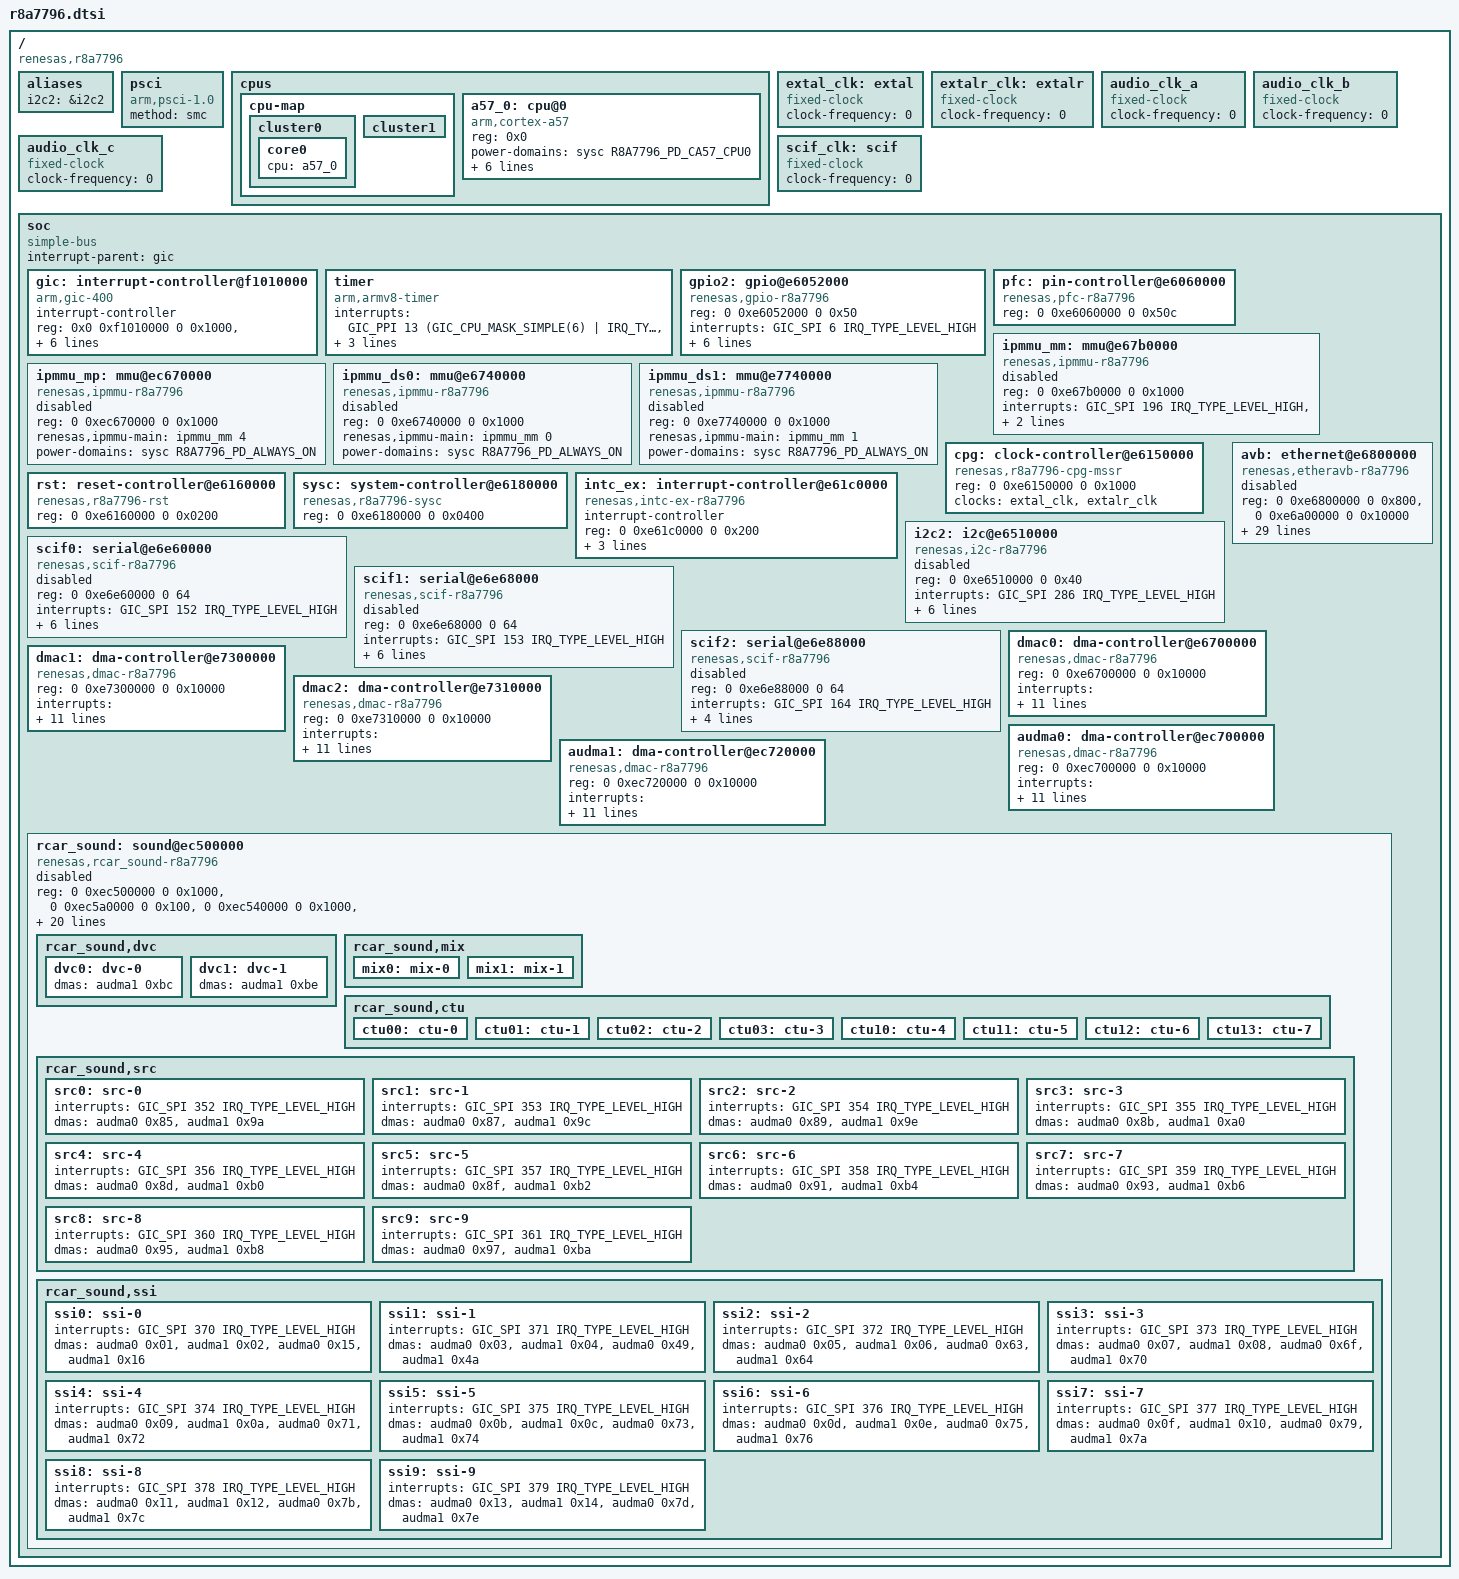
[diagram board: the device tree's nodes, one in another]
/*
 * Device Tree Source for the r8a7796 SoC
 *
 * Copyright (C) 2016-2018 Renesas Electronics Corp.
 *
 * This file is licensed under the terms of the GNU General Public License
 * version 2.  This program is licensed "as is" without any warranty of any
 * kind, whether express or implied.
 */

#include <dt-bindings/clock/r8a7796-cpg-mssr.h>
#include <dt-bindings/interrupt-controller/arm-gic.h>
#include <dt-bindings/power/r8a7796-sysc.h>

#define CPG_AUDIO_CLK_I		R8A7796_CLK_S0D4

/ {
	compatible = "renesas,r8a7796";
	#address-cells = <2>;
	#size-cells = <2>;

	aliases {
		i2c2 = &i2c2;
	};

	psci {
		compatible = "arm,psci-1.0", "arm,psci-0.2";
		method = "smc";
	};

	cpus {
		#address-cells = <1>;
		#size-cells = <0>;

		cpu-map {
			cluster0 {
				core0 {
					cpu = <&a57_0>;
				};
			};

			cluster1 {
			};
		};

		a57_0: cpu@0 {
			compatible = "arm,cortex-a57", "arm,armv8";
			reg = <0x0>;
			device_type = "cpu";
			power-domains = <&sysc R8A7796_PD_CA57_CPU0>;
			enable-method = "psci";
			#cooling-cells = <2>;
			dynamic-power-coefficient = <854>;
			cooling-min-level = <0>;
			cooling-max-level = <2>;
			clocks =<&cpg CPG_CORE R8A7796_CLK_Z>;
			capacity-dmips-mhz = <1024>;
		};
	};

	extal_clk: extal {
		compatible = "fixed-clock";
		#clock-cells = <0>;
		/* This value must be overridden by the board */
		clock-frequency = <0>;
	};

	extalr_clk: extalr {
		compatible = "fixed-clock";
		#clock-cells = <0>;
		/* This value must be overridden by the board */
		clock-frequency = <0>;
	};

	/*
	 * The external audio clocks are configured as 0 Hz fixed frequency
	 * clocks by default.
	 * Boards that provide audio clocks should override them.
	 */
	audio_clk_a: audio_clk_a {
		compatible = "fixed-clock";
		#clock-cells = <0>;
		clock-frequency = <0>;
	};

	audio_clk_b: audio_clk_b {
		compatible = "fixed-clock";
		#clock-cells = <0>;
		clock-frequency = <0>;
	};

	audio_clk_c: audio_clk_c {
		compatible = "fixed-clock";
		#clock-cells = <0>;
		clock-frequency = <0>;
	};


	/* External SCIF clock - to be overridden by boards that provide it */
	scif_clk: scif {
		compatible = "fixed-clock";
		#clock-cells = <0>;
		clock-frequency = <0>;
	};

	soc {
		compatible = "simple-bus";
		interrupt-parent = <&gic>;
		#address-cells = <2>;
		#size-cells = <2>;
		ranges;

		gic: interrupt-controller@f1010000 {
			compatible = "arm,gic-400";
			#interrupt-cells = <3>;
			#address-cells = <0>;
			interrupt-controller;
			reg = <0x0 0xf1010000 0 0x1000>,
			      <0x0 0xf1020000 0 0x20000>,
			      <0x0 0xf1040000 0 0x20000>,
			      <0x0 0xf1060000 0 0x20000>;
			interrupts = <GIC_PPI 9
					(GIC_CPU_MASK_SIMPLE(6) | IRQ_TYPE_LEVEL_HIGH)>;
			power-domains = <&sysc R8A7796_PD_ALWAYS_ON>;
		};

		timer {
			compatible = "arm,armv8-timer";
			interrupts = <GIC_PPI 13
					(GIC_CPU_MASK_SIMPLE(6) | IRQ_TYPE_LEVEL_LOW)>,
				     <GIC_PPI 14
					(GIC_CPU_MASK_SIMPLE(6) | IRQ_TYPE_LEVEL_LOW)>,
				     <GIC_PPI 11
					(GIC_CPU_MASK_SIMPLE(6) | IRQ_TYPE_LEVEL_LOW)>,
				     <GIC_PPI 10
					(GIC_CPU_MASK_SIMPLE(6) | IRQ_TYPE_LEVEL_LOW)>;
		};

		gpio2: gpio@e6052000 {
			compatible = "renesas,gpio-r8a7796",
				     "renesas,rcar-gen3-gpio";
			reg = <0 0xe6052000 0 0x50>;
			interrupts = <GIC_SPI 6 IRQ_TYPE_LEVEL_HIGH>;
			#gpio-cells = <2>;
			gpio-controller;
			gpio-ranges = <&pfc 0 64 15>;
			#interrupt-cells = <2>;
			interrupt-controller;
			clocks = <&cpg CPG_MOD 910>;
			power-domains = <&sysc R8A7796_PD_ALWAYS_ON>;
			resets = <&cpg 910>;
		};

		pfc: pin-controller@e6060000 {
			compatible = "renesas,pfc-r8a7796";
			reg = <0 0xe6060000 0 0x50c>;
		};


		ipmmu_mm: mmu@e67b0000 {
			compatible = "renesas,ipmmu-r8a7796";
			reg = <0 0xe67b0000 0 0x1000>;
			interrupts = <GIC_SPI 196 IRQ_TYPE_LEVEL_HIGH>,
				     <GIC_SPI 197 IRQ_TYPE_LEVEL_HIGH>;
			power-domains = <&sysc R8A7796_PD_ALWAYS_ON>;
			#iommu-cells = <1>;
			status = "disabled";
		};

		ipmmu_mp: mmu@ec670000 {
			compatible = "renesas,ipmmu-r8a7796";
			reg = <0 0xec670000 0 0x1000>;
			renesas,ipmmu-main = <&ipmmu_mm 4>;
			power-domains = <&sysc R8A7796_PD_ALWAYS_ON>;
			#iommu-cells = <1>;
			status = "disabled";
		};

		ipmmu_ds0: mmu@e6740000 {
			compatible = "renesas,ipmmu-r8a7796";
			reg = <0 0xe6740000 0 0x1000>;
			renesas,ipmmu-main = <&ipmmu_mm 0>;
			power-domains = <&sysc R8A7796_PD_ALWAYS_ON>;
			#iommu-cells = <1>;
			status = "disabled";
		};

		ipmmu_ds1: mmu@e7740000 {
			compatible = "renesas,ipmmu-r8a7796";
			reg = <0 0xe7740000 0 0x1000>;
			renesas,ipmmu-main = <&ipmmu_mm 1>;
			power-domains = <&sysc R8A7796_PD_ALWAYS_ON>;
			#iommu-cells = <1>;
			status = "disabled";
		};

		cpg: clock-controller@e6150000 {
			compatible = "renesas,r8a7796-cpg-mssr";
			reg = <0 0xe6150000 0 0x1000>;
			clocks = <&extal_clk>, <&extalr_clk>;
			clock-names = "extal", "extalr";
			#clock-cells = <2>;
			#power-domain-cells = <0>;
			#reset-cells = <1>;
		};

		rst: reset-controller@e6160000 {
			compatible = "renesas,r8a7796-rst";
			reg = <0 0xe6160000 0 0x0200>;
		};

		sysc: system-controller@e6180000 {
			compatible = "renesas,r8a7796-sysc";
			reg = <0 0xe6180000 0 0x0400>;
			#power-domain-cells = <1>;
		};

		intc_ex: interrupt-controller@e61c0000 {
			compatible = "renesas,intc-ex-r8a7796", "renesas,irqc";
			#interrupt-cells = <2>;
			interrupt-controller;
			reg = <0 0xe61c0000 0 0x200>;
			interrupts = <GIC_SPI 0 IRQ_TYPE_LEVEL_HIGH
				      GIC_SPI 1 IRQ_TYPE_LEVEL_HIGH
				      GIC_SPI 2 IRQ_TYPE_LEVEL_HIGH
				      GIC_SPI 3 IRQ_TYPE_LEVEL_HIGH
				      GIC_SPI 18 IRQ_TYPE_LEVEL_HIGH
				      GIC_SPI 161 IRQ_TYPE_LEVEL_HIGH>;
			power-domains = <&sysc R8A7796_PD_ALWAYS_ON>;
		};

		i2c2: i2c@e6510000 {
			#address-cells = <1>;
			#size-cells = <0>;
			compatible = "renesas,i2c-r8a7796",
				     "renesas,rcar-gen3-i2c";
			reg = <0 0xe6510000 0 0x40>;
			interrupts = <GIC_SPI 286 IRQ_TYPE_LEVEL_HIGH>;
			clocks = <&cpg CPG_MOD 929>;
			power-domains = <&sysc R8A7796_PD_ALWAYS_ON>;
			resets = <&cpg 929>;
			dmas = <&dmac1 0x95>, <&dmac1 0x94>,
			       <&dmac2 0x95>, <&dmac2 0x94>;
			dma-names = "tx", "rx", "tx", "rx";
			i2c-scl-internal-delay-ns = <6>;
			status = "disabled";
		};

		avb: ethernet@e6800000 {
			compatible = "renesas,etheravb-r8a7796",
				     "renesas,etheravb-rcar-gen3";
			reg = <0 0xe6800000 0 0x800>, <0 0xe6a00000 0 0x10000>;
			interrupts = <GIC_SPI 39 IRQ_TYPE_LEVEL_HIGH>,
				     <GIC_SPI 40 IRQ_TYPE_LEVEL_HIGH>,
				     <GIC_SPI 41 IRQ_TYPE_LEVEL_HIGH>,
				     <GIC_SPI 42 IRQ_TYPE_LEVEL_HIGH>,
				     <GIC_SPI 43 IRQ_TYPE_LEVEL_HIGH>,
				     <GIC_SPI 44 IRQ_TYPE_LEVEL_HIGH>,
				     <GIC_SPI 45 IRQ_TYPE_LEVEL_HIGH>,
				     <GIC_SPI 46 IRQ_TYPE_LEVEL_HIGH>,
				     <GIC_SPI 47 IRQ_TYPE_LEVEL_HIGH>,
				     <GIC_SPI 48 IRQ_TYPE_LEVEL_HIGH>,
				     <GIC_SPI 49 IRQ_TYPE_LEVEL_HIGH>,
				     <GIC_SPI 50 IRQ_TYPE_LEVEL_HIGH>,
				     <GIC_SPI 51 IRQ_TYPE_LEVEL_HIGH>,
				     <GIC_SPI 52 IRQ_TYPE_LEVEL_HIGH>,
				     <GIC_SPI 53 IRQ_TYPE_LEVEL_HIGH>,
				     <GIC_SPI 54 IRQ_TYPE_LEVEL_HIGH>,
				     <GIC_SPI 55 IRQ_TYPE_LEVEL_HIGH>,
				     <GIC_SPI 56 IRQ_TYPE_LEVEL_HIGH>,
				     <GIC_SPI 57 IRQ_TYPE_LEVEL_HIGH>,
				     <GIC_SPI 58 IRQ_TYPE_LEVEL_HIGH>,
				     <GIC_SPI 59 IRQ_TYPE_LEVEL_HIGH>,
				     <GIC_SPI 60 IRQ_TYPE_LEVEL_HIGH>,
				     <GIC_SPI 61 IRQ_TYPE_LEVEL_HIGH>,
				     <GIC_SPI 62 IRQ_TYPE_LEVEL_HIGH>,
				     <GIC_SPI 63 IRQ_TYPE_LEVEL_HIGH>;
			interrupt-names = "ch0", "ch1", "ch2", "ch3",
					  "ch4", "ch5", "ch6", "ch7",
					  "ch8", "ch9", "ch10", "ch11",
					  "ch12", "ch13", "ch14", "ch15",
					  "ch16", "ch17", "ch18", "ch19",
					  "ch20", "ch21", "ch22", "ch23",
					  "ch24";
			clocks = <&cpg CPG_MOD 812>;
			power-domains = <&sysc R8A7796_PD_ALWAYS_ON>;
			resets = <&cpg 812>;
			phy-mode = "rgmii-txid";
			#address-cells = <1>;
			#size-cells = <0>;
			status = "disabled";
		};

		scif0: serial@e6e60000 {
			compatible = "renesas,scif-r8a7796",
				     "renesas,rcar-gen3-scif", "renesas,scif";
			reg = <0 0xe6e60000 0 64>;
			interrupts = <GIC_SPI 152 IRQ_TYPE_LEVEL_HIGH>;
			clocks = <&cpg CPG_MOD 207>,
				 <&cpg CPG_CORE R8A7796_CLK_S3D1>,
				 <&scif_clk>;
			clock-names = "fck", "brg_int", "scif_clk";
			dmas = <&dmac1 0x51>, <&dmac1 0x50>,
			       <&dmac2 0x51>, <&dmac2 0x50>;
			dma-names = "tx", "rx", "tx", "rx";
			power-domains = <&sysc R8A7796_PD_ALWAYS_ON>;
			resets = <&cpg 207>;
			status = "disabled";
		};

		scif1: serial@e6e68000 {
			compatible = "renesas,scif-r8a7796",
				     "renesas,rcar-gen3-scif", "renesas,scif";
			reg = <0 0xe6e68000 0 64>;
			interrupts = <GIC_SPI 153 IRQ_TYPE_LEVEL_HIGH>;
			clocks = <&cpg CPG_MOD 206>,
				 <&cpg CPG_CORE R8A7796_CLK_S3D1>,
				 <&scif_clk>;
			clock-names = "fck", "brg_int", "scif_clk";
			dmas = <&dmac1 0x53>, <&dmac1 0x52>,
			       <&dmac2 0x53>, <&dmac2 0x52>;
			dma-names = "tx", "rx", "tx", "rx";
			power-domains = <&sysc R8A7796_PD_ALWAYS_ON>;
			resets = <&cpg 206>;
			status = "disabled";
		};


		scif2: serial@e6e88000 {
			compatible = "renesas,scif-r8a7796",
				     "renesas,rcar-gen3-scif", "renesas,scif";
			reg = <0 0xe6e88000 0 64>;
			interrupts = <GIC_SPI 164 IRQ_TYPE_LEVEL_HIGH>;
			clocks = <&cpg CPG_MOD 310>,
				 <&cpg CPG_CORE R8A7796_CLK_S3D1>,
				 <&scif_clk>;
			clock-names = "fck", "brg_int", "scif_clk";
			power-domains = <&sysc R8A7796_PD_ALWAYS_ON>;
			resets = <&cpg 310>;
			status = "disabled";
		};


		dmac0: dma-controller@e6700000 {
			compatible = "renesas,dmac-r8a7796",
				     "renesas,rcar-dmac";
			reg = <0 0xe6700000 0 0x10000>;
			interrupts = <GIC_SPI 200 IRQ_TYPE_LEVEL_HIGH
				      GIC_SPI 201 IRQ_TYPE_LEVEL_HIGH
				      GIC_SPI 202 IRQ_TYPE_LEVEL_HIGH
				      GIC_SPI 203 IRQ_TYPE_LEVEL_HIGH
				      GIC_SPI 204 IRQ_TYPE_LEVEL_HIGH
				      GIC_SPI 205 IRQ_TYPE_LEVEL_HIGH
				      GIC_SPI 206 IRQ_TYPE_LEVEL_HIGH
				      GIC_SPI 207 IRQ_TYPE_LEVEL_HIGH
				      GIC_SPI 208 IRQ_TYPE_LEVEL_HIGH
				      GIC_SPI 209 IRQ_TYPE_LEVEL_HIGH
				      GIC_SPI 210 IRQ_TYPE_LEVEL_HIGH
				      GIC_SPI 211 IRQ_TYPE_LEVEL_HIGH
				      GIC_SPI 212 IRQ_TYPE_LEVEL_HIGH
				      GIC_SPI 213 IRQ_TYPE_LEVEL_HIGH
				      GIC_SPI 214 IRQ_TYPE_LEVEL_HIGH
				      GIC_SPI 215 IRQ_TYPE_LEVEL_HIGH>;
			interrupt-names = "ch0", "ch1", "ch2", "ch3",
					"ch4", "ch5", "ch6", "ch7",
					"ch8", "ch9", "ch10", "ch11",
					"ch12", "ch13", "ch14", "ch15";
			clocks = <&cpg CPG_MOD 219>;
			clock-names = "fck";
			power-domains = <&sysc R8A7796_PD_ALWAYS_ON>;
			resets = <&cpg 219>;
			#dma-cells = <1>;
			dma-channels = <16>;
			iommus = <&ipmmu_ds0 0>, <&ipmmu_ds0 1>,
			       <&ipmmu_ds0 2>, <&ipmmu_ds0 3>,
			       <&ipmmu_ds0 4>, <&ipmmu_ds0 5>,
			       <&ipmmu_ds0 6>, <&ipmmu_ds0 7>,
			       <&ipmmu_ds0 8>, <&ipmmu_ds0 9>,
			       <&ipmmu_ds0 10>, <&ipmmu_ds0 11>,
			       <&ipmmu_ds0 12>, <&ipmmu_ds0 13>,
			       <&ipmmu_ds0 14>, <&ipmmu_ds0 15>;
		};

		dmac1: dma-controller@e7300000 {
			compatible = "renesas,dmac-r8a7796",
				     "renesas,rcar-dmac";
			reg = <0 0xe7300000 0 0x10000>;
			interrupts = <GIC_SPI 216 IRQ_TYPE_LEVEL_HIGH
				      GIC_SPI 217 IRQ_TYPE_LEVEL_HIGH
				      GIC_SPI 218 IRQ_TYPE_LEVEL_HIGH
				      GIC_SPI 219 IRQ_TYPE_LEVEL_HIGH
				      GIC_SPI 308 IRQ_TYPE_LEVEL_HIGH
				      GIC_SPI 309 IRQ_TYPE_LEVEL_HIGH
				      GIC_SPI 310 IRQ_TYPE_LEVEL_HIGH
				      GIC_SPI 311 IRQ_TYPE_LEVEL_HIGH
				      GIC_SPI 312 IRQ_TYPE_LEVEL_HIGH
				      GIC_SPI 313 IRQ_TYPE_LEVEL_HIGH
				      GIC_SPI 314 IRQ_TYPE_LEVEL_HIGH
				      GIC_SPI 315 IRQ_TYPE_LEVEL_HIGH
				      GIC_SPI 316 IRQ_TYPE_LEVEL_HIGH
				      GIC_SPI 317 IRQ_TYPE_LEVEL_HIGH
				      GIC_SPI 318 IRQ_TYPE_LEVEL_HIGH
				      GIC_SPI 319 IRQ_TYPE_LEVEL_HIGH>;
			interrupt-names = "ch0", "ch1", "ch2", "ch3",
					"ch4", "ch5", "ch6", "ch7",
					"ch8", "ch9", "ch10", "ch11",
					"ch12", "ch13", "ch14", "ch15";
			clocks = <&cpg CPG_MOD 218>;
			clock-names = "fck";
			power-domains = <&sysc R8A7796_PD_ALWAYS_ON>;
			resets = <&cpg 218>;
			#dma-cells = <1>;
			dma-channels = <16>;
			iommus = <&ipmmu_ds1 0>, <&ipmmu_ds1 1>,
			       <&ipmmu_ds1 2>, <&ipmmu_ds1 3>,
			       <&ipmmu_ds1 4>, <&ipmmu_ds1 5>,
			       <&ipmmu_ds1 6>, <&ipmmu_ds1 7>,
			       <&ipmmu_ds1 8>, <&ipmmu_ds1 9>,
			       <&ipmmu_ds1 10>, <&ipmmu_ds1 11>,
			       <&ipmmu_ds1 12>, <&ipmmu_ds1 13>,
			       <&ipmmu_ds1 14>, <&ipmmu_ds1 15>;
		};

		dmac2: dma-controller@e7310000 {
			compatible = "renesas,dmac-r8a7796",
				     "renesas,rcar-dmac";
			reg = <0 0xe7310000 0 0x10000>;
			interrupts = <GIC_SPI 417 IRQ_TYPE_LEVEL_HIGH
				      GIC_SPI 418 IRQ_TYPE_LEVEL_HIGH
				      GIC_SPI 419 IRQ_TYPE_LEVEL_HIGH
				      GIC_SPI 420 IRQ_TYPE_LEVEL_HIGH
				      GIC_SPI 421 IRQ_TYPE_LEVEL_HIGH
				      GIC_SPI 422 IRQ_TYPE_LEVEL_HIGH
				      GIC_SPI 423 IRQ_TYPE_LEVEL_HIGH
				      GIC_SPI 424 IRQ_TYPE_LEVEL_HIGH
				      GIC_SPI 425 IRQ_TYPE_LEVEL_HIGH
				      GIC_SPI 426 IRQ_TYPE_LEVEL_HIGH
				      GIC_SPI 427 IRQ_TYPE_LEVEL_HIGH
				      GIC_SPI 428 IRQ_TYPE_LEVEL_HIGH
				      GIC_SPI 429 IRQ_TYPE_LEVEL_HIGH
				      GIC_SPI 430 IRQ_TYPE_LEVEL_HIGH
				      GIC_SPI 431 IRQ_TYPE_LEVEL_HIGH
				      GIC_SPI 397 IRQ_TYPE_LEVEL_HIGH>;
			interrupt-names = "ch0", "ch1", "ch2", "ch3",
					"ch4", "ch5", "ch6", "ch7",
					"ch8", "ch9", "ch10", "ch11",
					"ch12", "ch13", "ch14", "ch15";
			clocks = <&cpg CPG_MOD 217>;
			clock-names = "fck";
			power-domains = <&sysc R8A7796_PD_ALWAYS_ON>;
			resets = <&cpg 217>;
			#dma-cells = <1>;
			dma-channels = <16>;
			iommus = <&ipmmu_ds1 16>, <&ipmmu_ds1 17>,
			       <&ipmmu_ds1 18>, <&ipmmu_ds1 19>,
			       <&ipmmu_ds1 20>, <&ipmmu_ds1 21>,
			       <&ipmmu_ds1 22>, <&ipmmu_ds1 23>,
			       <&ipmmu_ds1 24>, <&ipmmu_ds1 25>,
			       <&ipmmu_ds1 26>, <&ipmmu_ds1 27>,
			       <&ipmmu_ds1 28>, <&ipmmu_ds1 29>,
			       <&ipmmu_ds1 30>, <&ipmmu_ds1 31>;
		};

		audma0: dma-controller@ec700000 {
			compatible = "renesas,dmac-r8a7796",
				     "renesas,rcar-dmac";
			reg = <0 0xec700000 0 0x10000>;
			interrupts = <GIC_SPI 350 IRQ_TYPE_LEVEL_HIGH
				      GIC_SPI 320 IRQ_TYPE_LEVEL_HIGH
				      GIC_SPI 321 IRQ_TYPE_LEVEL_HIGH
				      GIC_SPI 322 IRQ_TYPE_LEVEL_HIGH
				      GIC_SPI 323 IRQ_TYPE_LEVEL_HIGH
				      GIC_SPI 324 IRQ_TYPE_LEVEL_HIGH
				      GIC_SPI 325 IRQ_TYPE_LEVEL_HIGH
				      GIC_SPI 326 IRQ_TYPE_LEVEL_HIGH
				      GIC_SPI 327 IRQ_TYPE_LEVEL_HIGH
				      GIC_SPI 328 IRQ_TYPE_LEVEL_HIGH
				      GIC_SPI 329 IRQ_TYPE_LEVEL_HIGH
				      GIC_SPI 330 IRQ_TYPE_LEVEL_HIGH
				      GIC_SPI 331 IRQ_TYPE_LEVEL_HIGH
				      GIC_SPI 332 IRQ_TYPE_LEVEL_HIGH
				      GIC_SPI 333 IRQ_TYPE_LEVEL_HIGH
				      GIC_SPI 334 IRQ_TYPE_LEVEL_HIGH
				      GIC_SPI 335 IRQ_TYPE_LEVEL_HIGH>;
			interrupt-names = "error",
					"ch0", "ch1", "ch2", "ch3",
					"ch4", "ch5", "ch6", "ch7",
					"ch8", "ch9", "ch10", "ch11",
					"ch12", "ch13", "ch14", "ch15";
			clocks = <&cpg CPG_MOD 502>;
			clock-names = "fck";
			power-domains = <&sysc R8A7796_PD_ALWAYS_ON>;
			resets = <&cpg 502>;
			#dma-cells = <1>;
			dma-channels = <16>;
			iommus = <&ipmmu_mp 0>, <&ipmmu_mp 1>,
			       <&ipmmu_mp 2>, <&ipmmu_mp 3>,
			       <&ipmmu_mp 4>, <&ipmmu_mp 5>,
			       <&ipmmu_mp 6>, <&ipmmu_mp 7>,
			       <&ipmmu_mp 8>, <&ipmmu_mp 9>,
			       <&ipmmu_mp 10>, <&ipmmu_mp 11>,
			       <&ipmmu_mp 12>, <&ipmmu_mp 13>,
			       <&ipmmu_mp 14>, <&ipmmu_mp 15>;
		};

		audma1: dma-controller@ec720000 {
			compatible = "renesas,dmac-r8a7796",
				     "renesas,rcar-dmac";
			reg = <0 0xec720000 0 0x10000>;
			interrupts = <GIC_SPI 351 IRQ_TYPE_LEVEL_HIGH
				      GIC_SPI 336 IRQ_TYPE_LEVEL_HIGH
				      GIC_SPI 337 IRQ_TYPE_LEVEL_HIGH
				      GIC_SPI 338 IRQ_TYPE_LEVEL_HIGH
				      GIC_SPI 339 IRQ_TYPE_LEVEL_HIGH
				      GIC_SPI 340 IRQ_TYPE_LEVEL_HIGH
				      GIC_SPI 341 IRQ_TYPE_LEVEL_HIGH
				      GIC_SPI 342 IRQ_TYPE_LEVEL_HIGH
				      GIC_SPI 343 IRQ_TYPE_LEVEL_HIGH
				      GIC_SPI 344 IRQ_TYPE_LEVEL_HIGH
				      GIC_SPI 345 IRQ_TYPE_LEVEL_HIGH
				      GIC_SPI 346 IRQ_TYPE_LEVEL_HIGH
				      GIC_SPI 347 IRQ_TYPE_LEVEL_HIGH
				      GIC_SPI 348 IRQ_TYPE_LEVEL_HIGH
				      GIC_SPI 349 IRQ_TYPE_LEVEL_HIGH
				      GIC_SPI 382 IRQ_TYPE_LEVEL_HIGH
				      GIC_SPI 383 IRQ_TYPE_LEVEL_HIGH>;
			interrupt-names = "error",
					"ch0", "ch1", "ch2", "ch3",
					"ch4", "ch5", "ch6", "ch7",
					"ch8", "ch9", "ch10", "ch11",
					"ch12", "ch13", "ch14", "ch15";
			clocks = <&cpg CPG_MOD 501>;
			clock-names = "fck";
			power-domains = <&sysc R8A7796_PD_ALWAYS_ON>;
			resets = <&cpg 501>;
			#dma-cells = <1>;
			dma-channels = <16>;
			iommus = <&ipmmu_mp 16>, <&ipmmu_mp 17>,
			       <&ipmmu_mp 18>, <&ipmmu_mp 19>,
			       <&ipmmu_mp 20>, <&ipmmu_mp 21>,
			       <&ipmmu_mp 22>, <&ipmmu_mp 23>,
			       <&ipmmu_mp 24>, <&ipmmu_mp 25>,
			       <&ipmmu_mp 26>, <&ipmmu_mp 27>,
			       <&ipmmu_mp 28>, <&ipmmu_mp 29>,
			       <&ipmmu_mp 30>, <&ipmmu_mp 31>;
		};

		rcar_sound: sound@ec500000 {
			/*
			 * #sound-dai-cells is required
			 *
			 * Single DAI : #sound-dai-cells = <0>;	<&rcar_sound>;
			 * Multi  DAI : #sound-dai-cells = <1>;	<&rcar_sound N>;
			 */
			/*
			 * #clock-cells is required for audio_clkout0/1/2/3
			 *
			 * clkout	: #clock-cells = <0>;	<&rcar_sound>;
			 * clkout0/1/2/3: #clock-cells = <1>;	<&rcar_sound N>;
			 */
			compatible =  "renesas,rcar_sound-r8a7796", "renesas,rcar_sound-gen3";
			reg =	<0 0xec500000 0 0x1000>, /* SCU */
				<0 0xec5a0000 0 0x100>,  /* ADG */
				<0 0xec540000 0 0x1000>, /* SSIU */
				<0 0xec541000 0 0x280>,  /* SSI */
				<0 0xec740000 0 0x200>;  /* Audio DMAC peri peri*/
			reg-names = "scu", "adg", "ssiu", "ssi", "audmapp";

			clocks = <&cpg CPG_MOD 1005>,
				 <&cpg CPG_MOD 1006>, <&cpg CPG_MOD 1007>,
				 <&cpg CPG_MOD 1008>, <&cpg CPG_MOD 1009>,
				 <&cpg CPG_MOD 1010>, <&cpg CPG_MOD 1011>,
				 <&cpg CPG_MOD 1012>, <&cpg CPG_MOD 1013>,
				 <&cpg CPG_MOD 1014>, <&cpg CPG_MOD 1015>,
				 <&cpg CPG_MOD 1022>, <&cpg CPG_MOD 1023>,
				 <&cpg CPG_MOD 1024>, <&cpg CPG_MOD 1025>,
				 <&cpg CPG_MOD 1026>, <&cpg CPG_MOD 1027>,
				 <&cpg CPG_MOD 1028>, <&cpg CPG_MOD 1029>,
				 <&cpg CPG_MOD 1030>, <&cpg CPG_MOD 1031>,
				 <&cpg CPG_MOD 1020>, <&cpg CPG_MOD 1021>,
				 <&cpg CPG_MOD 1020>, <&cpg CPG_MOD 1021>,
				 <&cpg CPG_MOD 1019>, <&cpg CPG_MOD 1018>,
				 <&audio_clk_a>, <&audio_clk_b>,
				 <&audio_clk_c>,
				 <&cpg CPG_CORE R8A7796_CLK_S0D4>;
			clock-names = "ssi-all",
				      "ssi.9", "ssi.8", "ssi.7", "ssi.6",
				      "ssi.5", "ssi.4", "ssi.3", "ssi.2",
				      "ssi.1", "ssi.0",
				      "src.9", "src.8", "src.7", "src.6",
				      "src.5", "src.4", "src.3", "src.2",
				      "src.1", "src.0",
				      "mix.1", "mix.0",
				      "ctu.1", "ctu.0",
				      "dvc.0", "dvc.1",
				      "clk_a", "clk_b", "clk_c", "clk_i";
			power-domains = <&sysc R8A7796_PD_ALWAYS_ON>;
			resets = <&cpg 1005>,
				 <&cpg 1006>, <&cpg 1007>,
				 <&cpg 1008>, <&cpg 1009>,
				 <&cpg 1010>, <&cpg 1011>,
				 <&cpg 1012>, <&cpg 1013>,
				 <&cpg 1014>, <&cpg 1015>;
			reset-names = "ssi-all",
				      "ssi.9", "ssi.8", "ssi.7", "ssi.6",
				      "ssi.5", "ssi.4", "ssi.3", "ssi.2",
				      "ssi.1", "ssi.0";
			status = "disabled";

			rcar_sound,dvc {
				dvc0: dvc-0 {
					dmas = <&audma1 0xbc>;
					dma-names = "tx";
				};
				dvc1: dvc-1 {
					dmas = <&audma1 0xbe>;
					dma-names = "tx";
				};
			};

			rcar_sound,mix {
				mix0: mix-0 { };
				mix1: mix-1 { };
			};

			rcar_sound,ctu {
				ctu00: ctu-0 { };
				ctu01: ctu-1 { };
				ctu02: ctu-2 { };
				ctu03: ctu-3 { };
				ctu10: ctu-4 { };
				ctu11: ctu-5 { };
				ctu12: ctu-6 { };
				ctu13: ctu-7 { };
			};

			rcar_sound,src {
				src0: src-0 {
					interrupts = <GIC_SPI 352 IRQ_TYPE_LEVEL_HIGH>;
					dmas = <&audma0 0x85>, <&audma1 0x9a>;
					dma-names = "rx", "tx";
				};
				src1: src-1 {
					interrupts = <GIC_SPI 353 IRQ_TYPE_LEVEL_HIGH>;
					dmas = <&audma0 0x87>, <&audma1 0x9c>;
					dma-names = "rx", "tx";
				};
				src2: src-2 {
					interrupts = <GIC_SPI 354 IRQ_TYPE_LEVEL_HIGH>;
					dmas = <&audma0 0x89>, <&audma1 0x9e>;
					dma-names = "rx", "tx";
				};
				src3: src-3 {
					interrupts = <GIC_SPI 355 IRQ_TYPE_LEVEL_HIGH>;
					dmas = <&audma0 0x8b>, <&audma1 0xa0>;
					dma-names = "rx", "tx";
				};
				src4: src-4 {
					interrupts = <GIC_SPI 356 IRQ_TYPE_LEVEL_HIGH>;
					dmas = <&audma0 0x8d>, <&audma1 0xb0>;
					dma-names = "rx", "tx";
				};
				src5: src-5 {
					interrupts = <GIC_SPI 357 IRQ_TYPE_LEVEL_HIGH>;
					dmas = <&audma0 0x8f>, <&audma1 0xb2>;
					dma-names = "rx", "tx";
				};
				src6: src-6 {
					interrupts = <GIC_SPI 358 IRQ_TYPE_LEVEL_HIGH>;
					dmas = <&audma0 0x91>, <&audma1 0xb4>;
					dma-names = "rx", "tx";
				};
				src7: src-7 {
					interrupts = <GIC_SPI 359 IRQ_TYPE_LEVEL_HIGH>;
					dmas = <&audma0 0x93>, <&audma1 0xb6>;
					dma-names = "rx", "tx";
				};
				src8: src-8 {
					interrupts = <GIC_SPI 360 IRQ_TYPE_LEVEL_HIGH>;
					dmas = <&audma0 0x95>, <&audma1 0xb8>;
					dma-names = "rx", "tx";
				};
				src9: src-9 {
					interrupts = <GIC_SPI 361 IRQ_TYPE_LEVEL_HIGH>;
					dmas = <&audma0 0x97>, <&audma1 0xba>;
					dma-names = "rx", "tx";
				};
			};

			rcar_sound,ssi {
				ssi0: ssi-0 {
					interrupts = <GIC_SPI 370 IRQ_TYPE_LEVEL_HIGH>;
					dmas = <&audma0 0x01>, <&audma1 0x02>, <&audma0 0x15>, <&audma1 0x16>;
					dma-names = "rx", "tx", "rxu", "txu";
				};
				ssi1: ssi-1 {
					interrupts = <GIC_SPI 371 IRQ_TYPE_LEVEL_HIGH>;
					dmas = <&audma0 0x03>, <&audma1 0x04>, <&audma0 0x49>, <&audma1 0x4a>;
					dma-names = "rx", "tx", "rxu", "txu";
				};
				ssi2: ssi-2 {
					interrupts = <GIC_SPI 372 IRQ_TYPE_LEVEL_HIGH>;
					dmas = <&audma0 0x05>, <&audma1 0x06>, <&audma0 0x63>, <&audma1 0x64>;
					dma-names = "rx", "tx", "rxu", "txu";
				};
				ssi3: ssi-3 {
					interrupts = <GIC_SPI 373 IRQ_TYPE_LEVEL_HIGH>;
					dmas = <&audma0 0x07>, <&audma1 0x08>, <&audma0 0x6f>, <&audma1 0x70>;
					dma-names = "rx", "tx", "rxu", "txu";
				};
				ssi4: ssi-4 {
					interrupts = <GIC_SPI 374 IRQ_TYPE_LEVEL_HIGH>;
					dmas = <&audma0 0x09>, <&audma1 0x0a>, <&audma0 0x71>, <&audma1 0x72>;
					dma-names = "rx", "tx", "rxu", "txu";
				};
				ssi5: ssi-5 {
					interrupts = <GIC_SPI 375 IRQ_TYPE_LEVEL_HIGH>;
					dmas = <&audma0 0x0b>, <&audma1 0x0c>, <&audma0 0x73>, <&audma1 0x74>;
					dma-names = "rx", "tx", "rxu", "txu";
				};
				ssi6: ssi-6 {
					interrupts = <GIC_SPI 376 IRQ_TYPE_LEVEL_HIGH>;
					dmas = <&audma0 0x0d>, <&audma1 0x0e>, <&audma0 0x75>, <&audma1 0x76>;
					dma-names = "rx", "tx", "rxu", "txu";
				};
				ssi7: ssi-7 {
					interrupts = <GIC_SPI 377 IRQ_TYPE_LEVEL_HIGH>;
					dmas = <&audma0 0x0f>, <&audma1 0x10>, <&audma0 0x79>, <&audma1 0x7a>;
					dma-names = "rx", "tx", "rxu", "txu";
				};
				ssi8: ssi-8 {
					interrupts = <GIC_SPI 378 IRQ_TYPE_LEVEL_HIGH>;
					dmas = <&audma0 0x11>, <&audma1 0x12>, <&audma0 0x7b>, <&audma1 0x7c>;
					dma-names = "rx", "tx", "rxu", "txu";
				};
				ssi9: ssi-9 {
					interrupts = <GIC_SPI 379 IRQ_TYPE_LEVEL_HIGH>;
					dmas = <&audma0 0x13>, <&audma1 0x14>, <&audma0 0x7d>, <&audma1 0x7e>;
					dma-names = "rx", "tx", "rxu", "txu";
				};
			};
		};

	};
};
